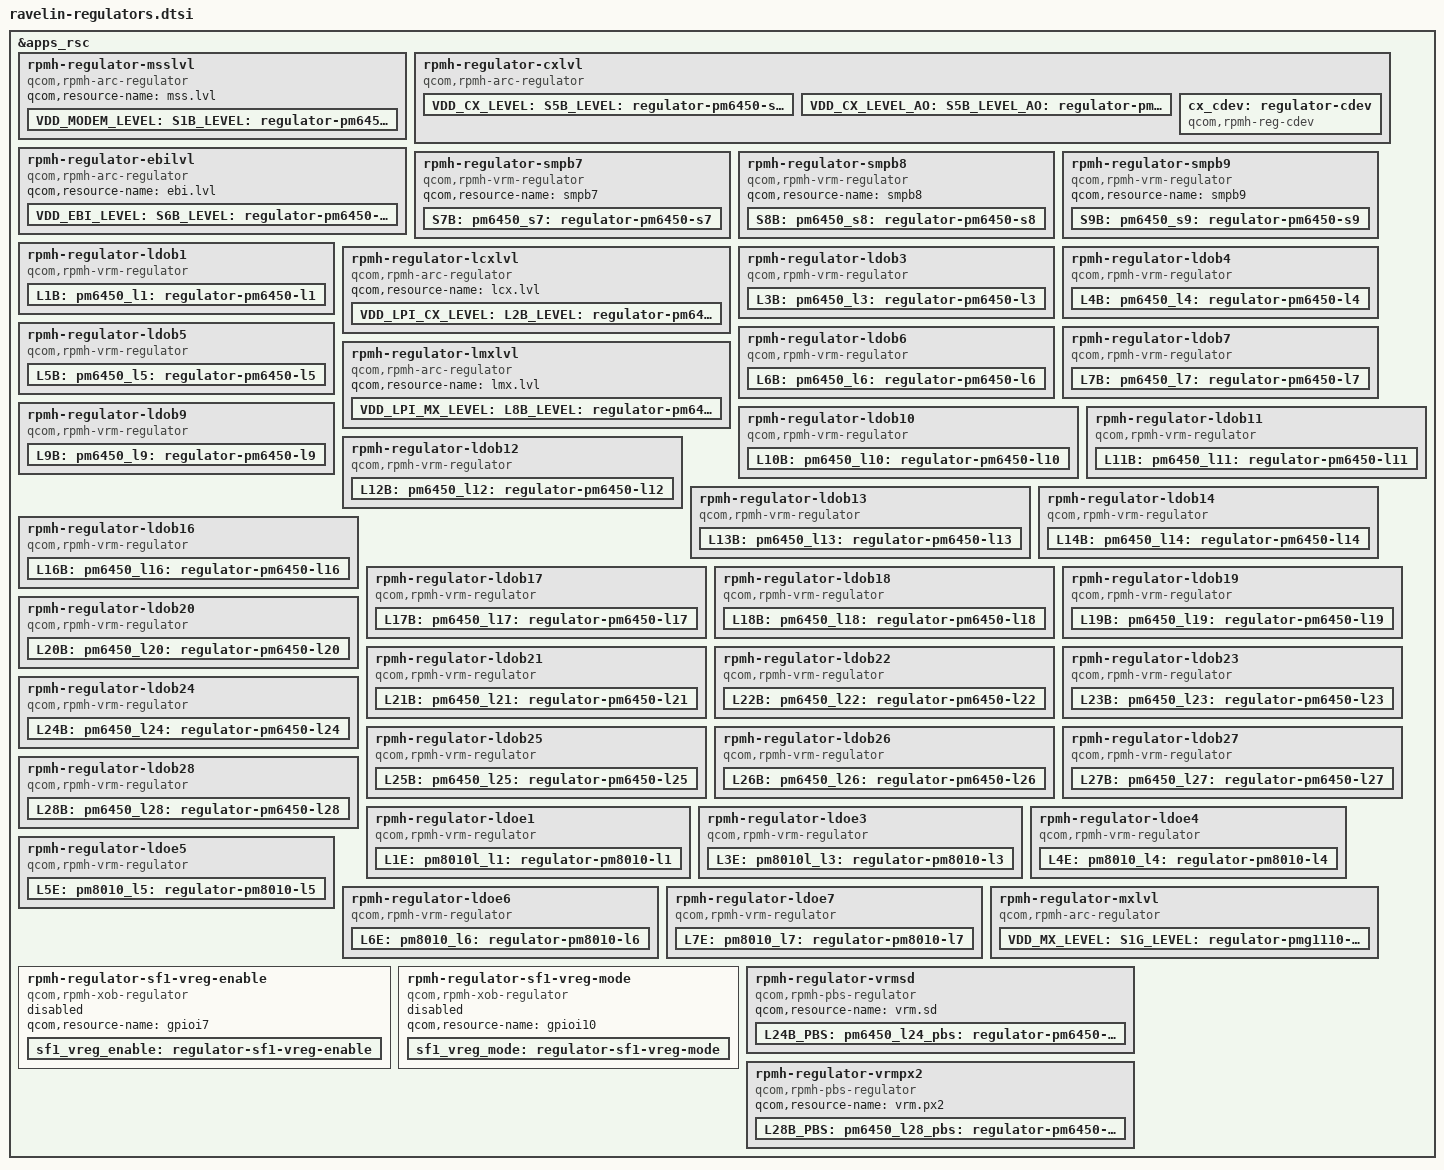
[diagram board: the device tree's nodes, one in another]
#include <dt-bindings/regulator/qcom,rpmh-regulator-levels.h>

&apps_rsc {
	rpmh-regulator-msslvl {
		compatible = "qcom,rpmh-arc-regulator";
		qcom,resource-name = "mss.lvl";
		VDD_MODEM_LEVEL:
		S1B_LEVEL:
		pm6450_s1_level: regulator-pm6450-s1-level {
			regulator-name = "pm6450_s1_level";
			qcom,set = <RPMH_REGULATOR_SET_ALL>;
			regulator-min-microvolt =
				<RPMH_REGULATOR_LEVEL_RETENTION>;
			regulator-max-microvolt = <RPMH_REGULATOR_LEVEL_MAX>;
			qcom,init-voltage-level =
				<RPMH_REGULATOR_LEVEL_RETENTION>;
		};
	};

	rpmh-regulator-cxlvl {
		compatible = "qcom,rpmh-arc-regulator";
		qcom,resource-name = "cx.lvl";
		proxy-supply = <&VDD_CX_LEVEL>;
		VDD_CX_LEVEL:
		S5B_LEVEL:
		pm6450_s5_level: regulator-pm6450-s5-level {
			regulator-name = "pm6450_s5_level";
			qcom,set = <RPMH_REGULATOR_SET_ALL>;
			regulator-min-microvolt =
				<RPMH_REGULATOR_LEVEL_RETENTION>;
			regulator-max-microvolt = <RPMH_REGULATOR_LEVEL_MAX>;
			qcom,init-voltage-level =
				<RPMH_REGULATOR_LEVEL_TURBO>;
			qcom,proxy-consumer-enable;
			qcom,proxy-consumer-voltage =
				<RPMH_REGULATOR_LEVEL_TURBO
				 RPMH_REGULATOR_LEVEL_MAX>;
		};

		VDD_CX_LEVEL_AO:
		S5B_LEVEL_AO:
		pm6450_s5_level_ao: regulator-pm6450-s5-level-ao {
			regulator-name = "pm6450_s5_level_ao";
			qcom,set = <RPMH_REGULATOR_SET_ACTIVE>;
			regulator-min-microvolt =
				<RPMH_REGULATOR_LEVEL_RETENTION>;
			regulator-max-microvolt = <RPMH_REGULATOR_LEVEL_MAX>;
			qcom,init-voltage-level =
				<RPMH_REGULATOR_LEVEL_RETENTION>;
		};

		cx_cdev: regulator-cdev {
			compatible = "qcom,rpmh-reg-cdev";
			mboxes = <&qmp_aop 0>;
			qcom,reg-resource-name = "cx";
			#cooling-cells = <2>;
		};
	};

	rpmh-regulator-ebilvl {
		compatible = "qcom,rpmh-arc-regulator";
		qcom,resource-name = "ebi.lvl";
		VDD_EBI_LEVEL:
		S6B_LEVEL:
		pm6450_s6_level: regulator-pm6450-s6-level {
			regulator-name = "pm6450_s6_level";
			qcom,set = <RPMH_REGULATOR_SET_ALL>;
			regulator-min-microvolt =
				<RPMH_REGULATOR_LEVEL_RETENTION>;
			regulator-max-microvolt = <RPMH_REGULATOR_LEVEL_MAX>;
			qcom,init-voltage-level =
				<RPMH_REGULATOR_LEVEL_RETENTION>;
		};
	};

	rpmh-regulator-smpb7 {
		compatible = "qcom,rpmh-vrm-regulator";
		qcom,resource-name = "smpb7";
		S7B:
		pm6450_s7: regulator-pm6450-s7 {
			regulator-name = "pm6450_s7";
			qcom,set = <RPMH_REGULATOR_SET_ALL>;
			regulator-min-microvolt = <1010000>;
			regulator-max-microvolt = <1170000>;
			qcom,init-voltage = <1120000>;
		};
	};

	rpmh-regulator-smpb8 {
		compatible = "qcom,rpmh-vrm-regulator";
		qcom,resource-name = "smpb8";
		S8B:
		pm6450_s8: regulator-pm6450-s8 {
			regulator-name = "pm6450_s8";
			qcom,set = <RPMH_REGULATOR_SET_ALL>;
			regulator-min-microvolt = <382000>;
			regulator-max-microvolt = <1744000>;
			qcom,init-voltage = <1352000>;
		};
	};

	rpmh-regulator-smpb9 {
		compatible = "qcom,rpmh-vrm-regulator";
		qcom,resource-name = "smpb9";
		S9B:
		pm6450_s9: regulator-pm6450-s9 {
			regulator-name = "pm6450_s9";
			qcom,set = <RPMH_REGULATOR_SET_ALL>;
			regulator-min-microvolt = <1856000>;
			regulator-max-microvolt = <2040000>;
			qcom,init-voltage = <1872000>;
		};
	};

	rpmh-regulator-ldob1 {
		compatible = "qcom,rpmh-vrm-regulator";
		qcom,resource-name = "ldob1";
		qcom,regulator-type = "pmic5-ldo";
		qcom,supported-modes =
			<RPMH_REGULATOR_MODE_LPM
			RPMH_REGULATOR_MODE_HPM>;
		qcom,mode-threshold-currents = <0 30000>;
		qcom,disable-mode = <RPMH_REGULATOR_MODE_LPM>;
		L1B:
		pm6450_l1: regulator-pm6450-l1 {
			regulator-name = "pm6450_l1";
			qcom,set = <RPMH_REGULATOR_SET_ALL>;
			regulator-min-microvolt = <312000>;
			regulator-max-microvolt = <650000>;
			qcom,init-voltage = <504000>;
			qcom,init-mode = <RPMH_REGULATOR_MODE_HPM>;
		};
	};

	rpmh-regulator-lcxlvl {
		compatible = "qcom,rpmh-arc-regulator";
		qcom,resource-name = "lcx.lvl";
		VDD_LPI_CX_LEVEL:
		L2B_LEVEL:
		pm6450_l2_level: regulator-pm6450-l2-level {
			regulator-name = "pm6450_l2_level";
			qcom,set = <RPMH_REGULATOR_SET_ALL>;
			regulator-min-microvolt =
				<RPMH_REGULATOR_LEVEL_RETENTION>;
			regulator-max-microvolt = <RPMH_REGULATOR_LEVEL_MAX>;
			qcom,init-voltage-level =
				<RPMH_REGULATOR_LEVEL_RETENTION>;
		};
	};

	rpmh-regulator-ldob3 {
		compatible = "qcom,rpmh-vrm-regulator";
		qcom,resource-name = "ldob3";
		qcom,regulator-type = "pmic5-ldo";
		qcom,supported-modes =
			<RPMH_REGULATOR_MODE_LPM
			RPMH_REGULATOR_MODE_HPM>;
		qcom,mode-threshold-currents = <0 30000>;
		qcom,disable-mode = <RPMH_REGULATOR_MODE_LPM>;
		L3B:
		pm6450_l3: regulator-pm6450-l3 {
			regulator-name = "pm6450_l3";
			qcom,set = <RPMH_REGULATOR_SET_ALL>;
			regulator-min-microvolt = <870000>;
			regulator-max-microvolt = <970000>;
			qcom,init-voltage = <904000>;
			qcom,init-mode = <RPMH_REGULATOR_MODE_HPM>;
		};
	};

	rpmh-regulator-ldob4 {
		compatible = "qcom,rpmh-vrm-regulator";
		qcom,resource-name = "ldob4";
		qcom,regulator-type = "pmic5-ldo";
		qcom,supported-modes =
			<RPMH_REGULATOR_MODE_LPM
			RPMH_REGULATOR_MODE_HPM>;
		qcom,mode-threshold-currents = <0 30000>;
		qcom,disable-mode = <RPMH_REGULATOR_MODE_LPM>;
		L4B:
		pm6450_l4: regulator-pm6450-l4 {
			regulator-name = "pm6450_l4";
			qcom,set = <RPMH_REGULATOR_SET_ALL>;
			regulator-min-microvolt = <530000>;
			regulator-max-microvolt = <860000>;
			qcom,init-voltage = <808000>;
			qcom,init-mode = <RPMH_REGULATOR_MODE_HPM>;
		};
	};

	rpmh-regulator-ldob5 {
		compatible = "qcom,rpmh-vrm-regulator";
		qcom,resource-name = "ldob5";
		qcom,regulator-type = "pmic5-ldo";
		qcom,supported-modes =
			<RPMH_REGULATOR_MODE_LPM
			RPMH_REGULATOR_MODE_HPM>;
		qcom,mode-threshold-currents = <0 30000>;
		qcom,disable-mode = <RPMH_REGULATOR_MODE_LPM>;
		L5B:
		pm6450_l5: regulator-pm6450-l5 {
			regulator-name = "pm6450_l4";
			qcom,set = <RPMH_REGULATOR_SET_ALL>;
			regulator-min-microvolt = <312000>;
			regulator-max-microvolt = <1052000>;
			qcom,init-voltage = <880000>;
			qcom,init-mode = <RPMH_REGULATOR_MODE_HPM>;
		};
	};

	rpmh-regulator-ldob6 {
		compatible = "qcom,rpmh-vrm-regulator";
		qcom,resource-name = "ldob6";
		qcom,regulator-type = "pmic5-ldo";
		qcom,supported-modes =
			<RPMH_REGULATOR_MODE_LPM
			RPMH_REGULATOR_MODE_HPM>;
		qcom,mode-threshold-currents = <0 30000>;
		qcom,disable-mode = <RPMH_REGULATOR_MODE_LPM>;
		L6B:
		pm6450_l6: regulator-pm6450-l6 {
			regulator-name = "pm6450_l6";
			qcom,set = <RPMH_REGULATOR_SET_ALL>;
			regulator-min-microvolt = <751000>;
			regulator-max-microvolt = <824000>;
			qcom,init-voltage = <824000>;
			qcom,init-mode = <RPMH_REGULATOR_MODE_HPM>;
		};
	};

	rpmh-regulator-ldob7 {
		compatible = "qcom,rpmh-vrm-regulator";
		qcom,resource-name = "ldob7";
		qcom,regulator-type = "pmic5-ldo";
		qcom,supported-modes =
			<RPMH_REGULATOR_MODE_LPM
			RPMH_REGULATOR_MODE_HPM>;
		qcom,mode-threshold-currents = <0 30000>;
		qcom,disable-mode = <RPMH_REGULATOR_MODE_LPM>;
		L7B:
		pm6450_l7: regulator-pm6450-l7 {
			regulator-name = "pm6450_l7";
			qcom,set = <RPMH_REGULATOR_SET_ALL>;
			regulator-min-microvolt = <830000>;
			regulator-max-microvolt = <920000>;
			qcom,init-voltage = <912000>;
			qcom,init-mode = <RPMH_REGULATOR_MODE_HPM>;
		};
	};

	rpmh-regulator-lmxlvl {
		compatible = "qcom,rpmh-arc-regulator";
		qcom,resource-name = "lmx.lvl";
		VDD_LPI_MX_LEVEL:
		L8B_LEVEL:
		pm6450_l8_level: regulator-pm6450-l8-level {
			regulator-name = "pm6450_l8_level";
			qcom,set = <RPMH_REGULATOR_SET_ALL>;
			regulator-min-microvolt =
				<RPMH_REGULATOR_LEVEL_RETENTION>;
			regulator-max-microvolt = <RPMH_REGULATOR_LEVEL_MAX>;
			qcom,init-voltage-level =
				<RPMH_REGULATOR_LEVEL_RETENTION>;
		};
	};

	rpmh-regulator-ldob9 {
		compatible = "qcom,rpmh-vrm-regulator";
		qcom,resource-name = "ldob9";
		qcom,regulator-type = "pmic5-ldo";
		qcom,supported-modes =
			<RPMH_REGULATOR_MODE_LPM
			RPMH_REGULATOR_MODE_HPM>;
		qcom,mode-threshold-currents = <0 30000>;
		qcom,disable-mode = <RPMH_REGULATOR_MODE_LPM>;
		L9B:
		pm6450_l9: regulator-pm6450-l9 {
			regulator-name = "pm6450_l9";
			qcom,set = <RPMH_REGULATOR_SET_ALL>;
			regulator-min-microvolt = <504000>;
			regulator-max-microvolt = <824000>;
			qcom,init-voltage = <752000>;
			qcom,init-mode = <RPMH_REGULATOR_MODE_HPM>;
		};
	};

	rpmh-regulator-ldob10 {
		compatible = "qcom,rpmh-vrm-regulator";
		qcom,resource-name = "ldob10";
		qcom,regulator-type = "pmic5-ldo";
		qcom,supported-modes =
			<RPMH_REGULATOR_MODE_LPM
			RPMH_REGULATOR_MODE_HPM>;
		qcom,mode-threshold-currents = <0 30000>;
		qcom,disable-mode = <RPMH_REGULATOR_MODE_LPM>;
		L10B:
		pm6450_l10: regulator-pm6450-l10 {
			regulator-name = "pm6450_l10";
			qcom,set = <RPMH_REGULATOR_SET_ALL>;
			regulator-min-microvolt = <824000>;
			regulator-max-microvolt = <901000>;
			qcom,init-voltage = <824000>;
			qcom,init-mode = <RPMH_REGULATOR_MODE_HPM>;
		};
	};

	rpmh-regulator-ldob11 {
		compatible = "qcom,rpmh-vrm-regulator";
		qcom,resource-name = "ldob11";
		qcom,regulator-type = "pmic5-ldo";
		qcom,supported-modes =
			<RPMH_REGULATOR_MODE_LPM
			RPMH_REGULATOR_MODE_HPM>;
		qcom,mode-threshold-currents = <0 30000>;
		qcom,disable-mode = <RPMH_REGULATOR_MODE_LPM>;
		L11B:
		pm6450_l11: regulator-pm6450-l11 {
			regulator-name = "pm6450_l11";
			qcom,set = <RPMH_REGULATOR_SET_ALL>;
			regulator-min-microvolt = <312000>;
			regulator-max-microvolt = <752000>;
			qcom,init-voltage = <348000>;
		};
	};

	rpmh-regulator-ldob12 {
		compatible = "qcom,rpmh-vrm-regulator";
		qcom,resource-name = "ldob12";
		qcom,regulator-type = "pmic5-ldo";
		qcom,supported-modes =
			<RPMH_REGULATOR_MODE_LPM
			RPMH_REGULATOR_MODE_HPM>;
		qcom,mode-threshold-currents = <0 30000>;
		qcom,disable-mode = <RPMH_REGULATOR_MODE_LPM>;
		L12B:
		pm6450_l12: regulator-pm6450-l12 {
			regulator-name = "pm6450_l12";
			qcom,set = <RPMH_REGULATOR_SET_ALL>;
			regulator-min-microvolt = <1080000>;
			regulator-max-microvolt = <1304000>;
			qcom,init-voltage = <1080000>;
			qcom,init-mode = <RPMH_REGULATOR_MODE_HPM>;
		};
	};

	rpmh-regulator-ldob13 {
		compatible = "qcom,rpmh-vrm-regulator";
		qcom,resource-name = "ldob13";
		qcom,regulator-type = "pmic5-ldo";
		qcom,supported-modes =
			<RPMH_REGULATOR_MODE_LPM
			RPMH_REGULATOR_MODE_HPM>;
		qcom,mode-threshold-currents = <0 30000>;
		qcom,disable-mode = <RPMH_REGULATOR_MODE_LPM>;
		L13B:
		pm6450_l13: regulator-pm6450-l13 {
			regulator-name = "pm6450_l13";
			qcom,set = <RPMH_REGULATOR_SET_ALL>;
			regulator-min-microvolt = <1080000>;
			regulator-max-microvolt = <1304000>;
			qcom,init-voltage = <1200000>;
			qcom,init-mode = <RPMH_REGULATOR_MODE_HPM>;
		};
	};

	rpmh-regulator-ldob14 {
		compatible = "qcom,rpmh-vrm-regulator";
		qcom,resource-name = "ldob14";
		qcom,regulator-type = "pmic5-ldo";
		qcom,supported-modes =
			<RPMH_REGULATOR_MODE_LPM
			RPMH_REGULATOR_MODE_HPM>;
		qcom,mode-threshold-currents = <0 30000>;
		qcom,disable-mode = <RPMH_REGULATOR_MODE_LPM>;
		L14B:
		pm6450_l14: regulator-pm6450-l14 {
			regulator-name = "pm6450_l14";
			qcom,set = <RPMH_REGULATOR_SET_ALL>;
			regulator-min-microvolt = <1245000>;
			regulator-max-microvolt = <1304000>;
			qcom,init-voltage = <1150000>;
			qcom,init-mode = <RPMH_REGULATOR_MODE_HPM>;
		};
	};

	rpmh-regulator-ldob16 {
		compatible = "qcom,rpmh-vrm-regulator";
		qcom,resource-name = "ldob16";
		qcom,regulator-type = "pmic5-ldo";
		qcom,supported-modes =
			<RPMH_REGULATOR_MODE_LPM
			RPMH_REGULATOR_MODE_HPM>;
		qcom,mode-threshold-currents = <0 30000>;
		qcom,disable-mode = <RPMH_REGULATOR_MODE_LPM>;
		L16B:
		pm6450_l16: regulator-pm6450-l16 {
			regulator-name = "pm6450_l16";
			qcom,set = <RPMH_REGULATOR_SET_ALL>;
			regulator-min-microvolt = <312000>;
			regulator-max-microvolt = <1260000>;
			qcom,init-voltage = <1200000>;
			qcom,init-mode = <RPMH_REGULATOR_MODE_HPM>;
		};
	};

	rpmh-regulator-ldob17 {
		compatible = "qcom,rpmh-vrm-regulator";
		qcom,resource-name = "ldob17";
		qcom,regulator-type = "pmic5-ldo";
		qcom,supported-modes =
			<RPMH_REGULATOR_MODE_LPM
			RPMH_REGULATOR_MODE_HPM>;
		qcom,mode-threshold-currents = <0 30000>;
		qcom,disable-mode = <RPMH_REGULATOR_MODE_LPM>;
		L17B:
		pm6450_l17: regulator-pm6450-l17 {
			regulator-name = "pm6450_l17";
			qcom,set = <RPMH_REGULATOR_SET_ALL>;
			regulator-min-microvolt = <1200000>;
			regulator-max-microvolt = <1200000>;
			qcom,init-voltage = <1200000>;
			qcom,init-mode = <RPMH_REGULATOR_MODE_HPM>;
		};
	};

	rpmh-regulator-ldob18 {
		compatible = "qcom,rpmh-vrm-regulator";
		qcom,resource-name = "ldob18";
		qcom,regulator-type = "pmic5-ldo";
		qcom,supported-modes =
			<RPMH_REGULATOR_MODE_LPM
			RPMH_REGULATOR_MODE_HPM>;
		qcom,mode-threshold-currents = <0 10000>;
		qcom,disable-mode = <RPMH_REGULATOR_MODE_LPM>;
		L18B:
		pm6450_l18: regulator-pm6450-l18 {
			regulator-name = "pm6450_l18";
			qcom,set = <RPMH_REGULATOR_SET_ALL>;
			regulator-min-microvolt = <1504000>;
			regulator-max-microvolt = <2000000>;
			qcom,init-voltage = <1504000>;
			qcom,init-mode = <RPMH_REGULATOR_MODE_HPM>;
		};
	};

	rpmh-regulator-ldob19 {
		compatible = "qcom,rpmh-vrm-regulator";
		qcom,resource-name = "ldob19";
		qcom,regulator-type = "pmic5-ldo";
		qcom,supported-modes =
			<RPMH_REGULATOR_MODE_LPM
			RPMH_REGULATOR_MODE_HPM>;
		qcom,mode-threshold-currents = <0 10000>;
		qcom,disable-mode = <RPMH_REGULATOR_MODE_LPM>;
		L19B:
		pm6450_l19: regulator-pm6450-l19 {
			regulator-name = "pm6450_l19";
			qcom,set = <RPMH_REGULATOR_SET_ALL>;
			regulator-min-microvolt = <1700000>;
			regulator-max-microvolt = <1950000>;
			qcom,init-voltage = <1800000>;
			qcom,init-mode = <RPMH_REGULATOR_MODE_HPM>;
		};
	};

	rpmh-regulator-ldob20 {
		compatible = "qcom,rpmh-vrm-regulator";
		qcom,resource-name = "ldob20";
		qcom,regulator-type = "pmic5-ldo";
		qcom,supported-modes =
			<RPMH_REGULATOR_MODE_LPM
			RPMH_REGULATOR_MODE_HPM>;
		qcom,mode-threshold-currents = <0 10000>;
		qcom,disable-mode = <RPMH_REGULATOR_MODE_LPM>;
		L20B:
		pm6450_l20: regulator-pm6450-l20 {
			regulator-name = "pm6450_l20";
			qcom,set = <RPMH_REGULATOR_SET_ALL>;
			regulator-min-microvolt = <1700000>;
			regulator-max-microvolt = <1900000>;
			qcom,init-voltage = <1700000>;
			qcom,init-mode = <RPMH_REGULATOR_MODE_HPM>;
		};
	};

	rpmh-regulator-ldob21 {
		compatible = "qcom,rpmh-vrm-regulator";
		qcom,resource-name = "ldob21";
		qcom,regulator-type = "pmic5-ldo";
		qcom,supported-modes =
			<RPMH_REGULATOR_MODE_LPM
			RPMH_REGULATOR_MODE_HPM>;
		qcom,mode-threshold-currents = <0 10000>;
		qcom,disable-mode = <RPMH_REGULATOR_MODE_LPM>;
		L21B:
		pm6450_l21: regulator-pm6450-l21 {
			regulator-name = "pm6450_l21";
			qcom,set = <RPMH_REGULATOR_SET_ALL>;
			regulator-min-microvolt = <1504000>;
			regulator-max-microvolt = <2000000>;
			qcom,init-voltage = <1800000>;
			qcom,init-mode = <RPMH_REGULATOR_MODE_HPM>;
		};
	};

	rpmh-regulator-ldob22 {
		compatible = "qcom,rpmh-vrm-regulator";
		qcom,resource-name = "ldob22";
		qcom,regulator-type = "pmic5-ldo";
		qcom,supported-modes =
			<RPMH_REGULATOR_MODE_LPM
			RPMH_REGULATOR_MODE_HPM>;
		qcom,mode-threshold-currents = <0 10000>;
		qcom,disable-mode = <RPMH_REGULATOR_MODE_LPM>;
		L22B:
		pm6450_l22: regulator-pm6450-l22 {
			regulator-name = "pm6450_l22";
			qcom,set = <RPMH_REGULATOR_SET_ALL>;
			regulator-min-microvolt = <1504000>;
			regulator-max-microvolt = <2000000>;
			qcom,init-voltage = <1800000>;
			qcom,init-mode = <RPMH_REGULATOR_MODE_HPM>;
		};
	};

	rpmh-regulator-ldob23 {
		compatible = "qcom,rpmh-vrm-regulator";
		qcom,resource-name = "ldob23";
		qcom,regulator-type = "pmic5-ldo";
		qcom,supported-modes =
			<RPMH_REGULATOR_MODE_LPM
			RPMH_REGULATOR_MODE_HPM>;
		qcom,mode-threshold-currents = <0 10000>;
		qcom,disable-mode = <RPMH_REGULATOR_MODE_LPM>;
		L23B:
		pm6450_l23: regulator-pm6450-l23 {
			regulator-name = "pm6450_l23";
			qcom,set = <RPMH_REGULATOR_SET_ALL>;
			regulator-min-microvolt = <1620000>;
			regulator-max-microvolt = <1980000>;
			qcom,init-voltage = <1800000>;
			qcom,init-mode = <RPMH_REGULATOR_MODE_HPM>;
		};
	};

	rpmh-regulator-ldob24 {
		compatible = "qcom,rpmh-vrm-regulator";
		qcom,resource-name = "ldob24";
		qcom,regulator-type = "pmic5-ldo";
		qcom,supported-modes =
			<RPMH_REGULATOR_MODE_LPM
			RPMH_REGULATOR_MODE_HPM>;
		qcom,mode-threshold-currents = <0 10000>;
		qcom,disable-mode = <RPMH_REGULATOR_MODE_LPM>;
		L24B:
		pm6450_l24: regulator-pm6450-l24 {
			regulator-name = "pm6450_l24";
			qcom,set = <RPMH_REGULATOR_SET_ALL>;
			regulator-min-microvolt = <2700000>;
			regulator-max-microvolt = <3544000>;
			qcom,init-voltage = <2700000>;
			qcom,init-mode = <RPMH_REGULATOR_MODE_HPM>;
		};
	};

	rpmh-regulator-ldob25 {
		compatible = "qcom,rpmh-vrm-regulator";
		qcom,resource-name = "ldob25";
		qcom,regulator-type = "pmic5-ldo";
		qcom,supported-modes =
			<RPMH_REGULATOR_MODE_LPM
			RPMH_REGULATOR_MODE_HPM>;
		qcom,mode-threshold-currents = <0 10000>;
		qcom,disable-mode = <RPMH_REGULATOR_MODE_LPM>;
		L25B:
		pm6450_l25: regulator-pm6450-l25 {
			regulator-name = "pm6450_l25";
			qcom,set = <RPMH_REGULATOR_SET_ALL>;
			regulator-min-microvolt = <2700000>;
			regulator-max-microvolt = <3544000>;
			qcom,init-voltage = <3072000>;
			qcom,init-mode = <RPMH_REGULATOR_MODE_HPM>;
		};
	};

	rpmh-regulator-ldob26 {
		compatible = "qcom,rpmh-vrm-regulator";
		qcom,resource-name = "ldob26";
		qcom,regulator-type = "pmic5-ldo";
		qcom,supported-modes =
			<RPMH_REGULATOR_MODE_LPM
			RPMH_REGULATOR_MODE_HPM>;
		qcom,mode-threshold-currents = <0 10000>;
		qcom,disable-mode = <RPMH_REGULATOR_MODE_LPM>;
		L26B:
		pm6450_l26: regulator-pm6450-l26 {
			regulator-name = "pm6450_l26";
			qcom,set = <RPMH_REGULATOR_SET_ALL>;
			regulator-min-microvolt = <1620000>;
			regulator-max-microvolt = <3300000>;
			qcom,init-voltage = <1620000>;
			qcom,init-mode = <RPMH_REGULATOR_MODE_HPM>;
		};
	};

	rpmh-regulator-ldob27 {
		compatible = "qcom,rpmh-vrm-regulator";
		qcom,resource-name = "ldob27";
		qcom,regulator-type = "pmic5-ldo";
		qcom,supported-modes =
			<RPMH_REGULATOR_MODE_LPM
			RPMH_REGULATOR_MODE_HPM>;
		qcom,mode-threshold-currents = <0 10000>;
		qcom,disable-mode = <RPMH_REGULATOR_MODE_LPM>;
		L27B:
		pm6450_l27: regulator-pm6450-l27 {
			regulator-name = "pm6450_l27";
			qcom,set = <RPMH_REGULATOR_SET_ALL>;
			regulator-min-microvolt = <1620000>;
			regulator-max-microvolt = <3300000>;
			qcom,init-voltage = <1620000>;
			qcom,init-mode = <RPMH_REGULATOR_MODE_HPM>;
		};
	};

	rpmh-regulator-ldob28 {
		compatible = "qcom,rpmh-vrm-regulator";
		qcom,resource-name = "ldob28";
		qcom,regulator-type = "pmic5-ldo";
		qcom,supported-modes =
			<RPMH_REGULATOR_MODE_LPM
			RPMH_REGULATOR_MODE_HPM>;
		qcom,mode-threshold-currents = <0 10000>;
		qcom,disable-mode = <RPMH_REGULATOR_MODE_LPM>;
		L28B:
		pm6450_l28: regulator-pm6450-l28 {
			regulator-name = "pm6450_l28";
			qcom,set = <RPMH_REGULATOR_SET_ALL>;
			regulator-min-microvolt = <1620000>;
			regulator-max-microvolt = <3300000>;
			qcom,init-voltage = <2700000>;
			qcom,init-mode = <RPMH_REGULATOR_MODE_HPM>;
		};
	};

	rpmh-regulator-ldoe1 {
		compatible = "qcom,rpmh-vrm-regulator";
		qcom,resource-name = "ldoe1";
		qcom,regulator-type = "pmic5-ldo";
		qcom,supported-modes =
			<RPMH_REGULATOR_MODE_LPM
			RPMH_REGULATOR_MODE_HPM>;
		qcom,mode-threshold-currents = <0 10000>;
		qcom,disable-mode = <RPMH_REGULATOR_MODE_LPM>;
		L1E:
		pm8010l_l1: regulator-pm8010-l1 {
			regulator-name = "pm8010_l1";
			qcom,set = <RPMH_REGULATOR_SET_ALL>;
			regulator-min-microvolt = <530000>;
			regulator-max-microvolt = <864000>;
			qcom,init-voltage = <530000>;
		};
	};

	rpmh-regulator-ldoe3 {
		compatible = "qcom,rpmh-vrm-regulator";
		qcom,resource-name = "ldoe3";
		qcom,regulator-type = "pmic5-ldo";
		/* mode voting is not allowed */
		L3E:
		pm8010l_l3: regulator-pm8010-l3 {
			regulator-name = "pm8010_l3";
			qcom,set = <RPMH_REGULATOR_SET_ALL>;
			regulator-min-microvolt = <2700000>;
			regulator-max-microvolt = <3300000>;
			qcom,init-voltage = <2700000>;
		};
	};

	rpmh-regulator-ldoe4 {
		compatible = "qcom,rpmh-vrm-regulator";
		qcom,resource-name = "ldoe4";
		qcom,regulator-type = "pmic5-ldo";
		/* mode voting is not allowed */
		L4E:
		pm8010_l4: regulator-pm8010-l4 {
			regulator-name = "pm8010_l4";
			qcom,set = <RPMH_REGULATOR_SET_ALL>;
			regulator-min-microvolt = <2600000>;
			regulator-max-microvolt = <3312000>;
			qcom,init-voltage = <2700000>;
		};
	};

	rpmh-regulator-ldoe5 {
		compatible = "qcom,rpmh-vrm-regulator";
		qcom,resource-name = "ldoe5";
		qcom,regulator-type = "pmic5-ldo";
		/* mode voting is not allowed */
		L5E:
		pm8010_l5: regulator-pm8010-l5 {
			regulator-name = "pm8010_l5";
			qcom,set = <RPMH_REGULATOR_SET_ALL>;
			/*
			 * Remove min/max voltages for this regulator as initial
			 * voltage of  L5E is set to be 2.4v/2.96v during PON
			 * depending upon the UFS mode. UFS is the only client
			 * on this and this regulator will only be voted
			 * for enabling/disabling conditions.
			 */
		};
	};

	rpmh-regulator-ldoe6 {
		compatible = "qcom,rpmh-vrm-regulator";
		qcom,resource-name = "ldoe6";
		qcom,regulator-type = "pmic5-ldo";
		/* mode voting is not allowed */
		L6E:
		pm8010_l6: regulator-pm8010-l6 {
			regulator-name = "pm8010_l6";
			qcom,set = <RPMH_REGULATOR_SET_ALL>;
			regulator-min-microvolt = <3000000>;
			regulator-max-microvolt = <3312000>;
			qcom,init-voltage = <3000000>;
		};
	};

	rpmh-regulator-ldoe7 {
		compatible = "qcom,rpmh-vrm-regulator";
		qcom,resource-name = "ldoe7";
		qcom,regulator-type = "pmic5-ldo";
		/* mode voting is not allowed */
		L7E:
		pm8010_l7: regulator-pm8010-l7 {
			regulator-name = "pm8010_l7";
			qcom,set = <RPMH_REGULATOR_SET_ALL>;
			regulator-min-microvolt = <2500000>;
			regulator-max-microvolt = <3544000>;
			qcom,init-voltage = <3000000>;
		};
	};

	rpmh-regulator-mxlvl {
		compatible = "qcom,rpmh-arc-regulator";
		qcom,resource-name = "mx.lvl";
		proxy-supply = <&VDD_MX_LEVEL>;

		VDD_MX_LEVEL:
		S1G_LEVEL:
		pmg1110_s1_level: regulator-pmg1110-s1-level {
			regulator-name = "pmg1110_s1_level";
			qcom,set = <RPMH_REGULATOR_SET_ALL>;
			regulator-min-microvolt =
				<RPMH_REGULATOR_LEVEL_RETENTION>;
			regulator-max-microvolt = <RPMH_REGULATOR_LEVEL_MAX>;
			qcom,init-voltage-level =
				<RPMH_REGULATOR_LEVEL_TURBO>;
			qcom,proxy-consumer-enable;
			qcom,proxy-consumer-voltage =
				<RPMH_REGULATOR_LEVEL_TURBO
				 RPMH_REGULATOR_LEVEL_MAX>;

		};
	};

	rpmh-regulator-sf1-vreg-enable {
		compatible = "qcom,rpmh-xob-regulator";
		qcom,resource-name = "gpioi7";
		status = "disabled";
		sf1_vreg_enable: regulator-sf1-vreg-enable {
			regulator-name = "sf1_vreg_enable";
			qcom,set = <RPMH_REGULATOR_SET_ALL>;
		};
	};

	rpmh-regulator-sf1-vreg-mode {
		compatible = "qcom,rpmh-xob-regulator";
		qcom,resource-name = "gpioi10";
		status = "disabled";
		sf1_vreg_mode: regulator-sf1-vreg-mode {
			regulator-name = "sf1_vreg_mode";
			qcom,set = <RPMH_REGULATOR_SET_ALL>;
		};
	};

	rpmh-regulator-vrmsd {
		compatible = "qcom,rpmh-pbs-regulator";
		qcom,resource-name = "vrm.sd";

		L24B_PBS:
		pm6450_l24_pbs: regulator-pm6450-l24-pbs {
			regulator-name = "pm6450_l24_pbs";
			qcom,set = <RPMH_REGULATOR_SET_ALL>;
			/*
			 * min/max voltages are voted on L24B and this regulator will
			 * only be voted for enabling/disabling conditions.
			 */
		};
	};

	rpmh-regulator-vrmpx2 {
		compatible = "qcom,rpmh-pbs-regulator";
		qcom,resource-name = "vrm.px2";

		L28B_PBS:
		pm6450_l28_pbs: regulator-pm6450-l28-pbs {
			regulator-name = "pm6450_l28_pbs";
			qcom,set = <RPMH_REGULATOR_SET_ALL>;
			/*
			 * min/max voltages are voted on L28B and this regulator will
			 * only be voted for enabling/disabling conditions.
			 */
		};
	};
};
